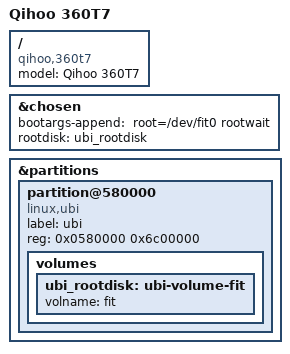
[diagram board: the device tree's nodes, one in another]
// SPDX-License-Identifier: GPL-2.0-or-later OR MIT

/dts-v1/;

#include "mt7981b-qihoo-360t7-base.dtsi"

/ {
	model = "Qihoo 360T7";
	compatible = "qihoo,360t7", "mediatek,mt7981";
};

&chosen {
	bootargs-append = " root=/dev/fit0 rootwait";
	rootdisk = <&ubi_rootdisk>;
};

&partitions {
	partition@580000 {
		label = "ubi";
		reg = <0x0580000 0x6c00000>;
		compatible = "linux,ubi";

		volumes {
			ubi_rootdisk: ubi-volume-fit {
				volname = "fit";
			};
		};
	};
};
